# MDR1206AFI register map
Vendor: Milandr; File version: 2.0
CPU: BM-310S0, little endian
Registers are 32-bit, read-write, reset 0x0 unless marked. A register's access mark holds for its fields unless they carry their own. Offsets are from the block's base; [hi:lo] are bit positions; {n}, {i} and the like mark numbered series.

## FLASH_CNTRL — FLASH Memory Controller
Base 0x50018000
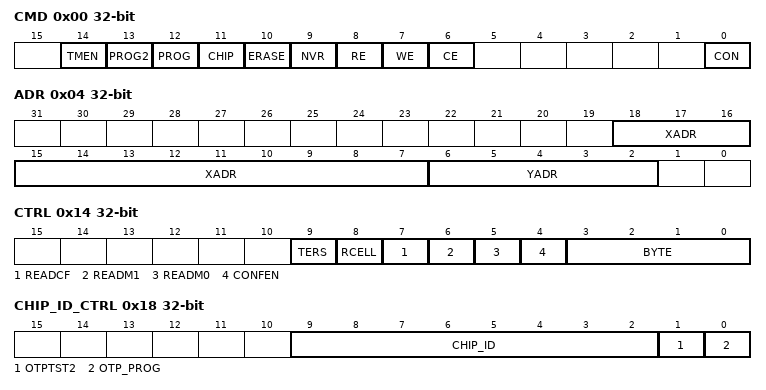
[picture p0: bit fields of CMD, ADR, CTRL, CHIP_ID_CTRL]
0x00 CMD — Control register
  [14] TMEN — Reset FLASH test mode
  [13] PROG2 — Write data from the DI register
  [12] PROG — Enable programming within 32 word lines
  [11] CHIP — Erase the entire sector when ERASE = 1
  [10] ERASE — Erase 512 byte memory page
  [9] NVR — Main/information block selection
  [8] RE — Reading amplifier
  [7] WE — Enable write/erase operations
  [6] CE — Output address ADR[17:2]
  [0] CON — Switching the FLASH memory controller to register control
0x04 ADR — Address register
  [18:7] XADR — Main: XADR[11] - sector number, XADR[10:2] - page address, XADR[1:0] - row address. Info: XADR[6] - sector number, XADR[5:2] - page address, XADR[1:0] - row address
  [6:2] YADR — Word address
0x08 DI — Write data register
0x0C DO — Read data register
0x10 KEY — Key register, 0x8AAA5551 unlocks access
0x14 CTRL — Control and test register
  [9] TERS — Test bit. Always write 0
  [8] RCELL — Test bit. Always write 0
  [7] READCF — Test bit. Always write 0
  [6] READM1 — Test bit. Always write 0
  [5] READM0 — Test bit. Always write 0
  [4] CONFEN — Test bit. Always write 0
  [3:0] BYTE — Selecting a byte from the DI register for programming operations
0x18 CHIP_ID_CTRL — Chip ID and OTP control register
  [9:2] CHIP_ID ro
    215=MDR1206AFI (ID=215); 217=MDR1206FI (ID=217)
  [1] OTPTST2 ro — Test bit
  [0] OTP_PROG — OTP cell program bit
0x1C OTP_KEY — OTP key register, 0x1555AAA8 unlocks access

## I2C — I2C Controller
Base 0x50030000
0x00 PRL — Lower part of the prescaler
  [7:0] PR
0x04 PRH — Higher part of the prescaler
  [7:0] PR
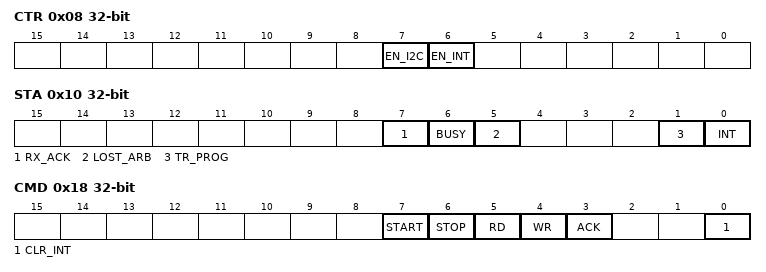
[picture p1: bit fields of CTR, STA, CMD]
0x08 CTR — I2C Control Register
  [7] EN_I2C — Enables I2C operation
  [6] EN_INT — Enables the interrupt generated by the I2C
0x0C RXD ro — Received Data Register
  [7:0] RXD — The last received byte
0x10 STA ro — Status Register
  [7] RX_ACK — Signals if ACK or NACK has been received from a Slave
    0=ACK_Received; 1=NACK_Received
  [6] BUSY — The state of the I2C bus
    0=Stop_Bit_Received; 1=Start_Bit_Received
  [5] LOST_ARB — The loss of the arbitration
    0=ARB_Present; 1=ARB_Lost (The arbitration has been lost. Stop bit has been received without initialization or SDA must be set as high but it is low)
  [1] TR_PROG — The state of the transmission
    0=Completed (Data transmission is completed); 1=In Progress (Data transmission is in progress)
  [0] INT — Interrupt flag
    0=No_Int (Selects ACLK as the clock source); 1=Int_Present (There is an interrupt. Either a byte has been transmitted or the arbitration has been lost)
0x14 TXD — Data for Transmission Register
  [7:0] TXD — Byte to be transmitted via I2C. When address is transmitted zero nit sets the mode^ 0 - write in a Salve, 1 - read out of a Slave
0x18 CMD — I2C Control Register
  [7] START — Sends the start bit
  [6] STOP — Sends the stop bit
  [5] RD — Reads the data of the slave device
  [4] WR — Writes into the slave device
  [3] ACK — Sends ACK
    0=Send_ACK; 1=Send_NACK
  [0] CLR_INT — A write as "1" clears the interrupt

## ADC — ADC Controller
Base 0x50040000
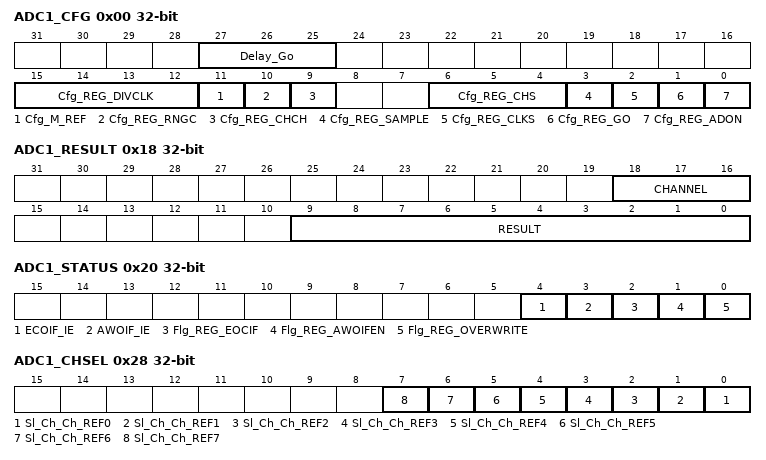
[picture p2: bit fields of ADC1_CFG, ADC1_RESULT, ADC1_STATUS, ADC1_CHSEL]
0x00 ADC1_CFG — ADC1 Configuration Register
  [27:25] Delay_Go — Selects a delay value before the next conversion
  [15:12] Cfg_REG_DIVCLK — Selects the divisor of PCLK
  [11] Cfg_M_REF — Selects the ADC range
    1=SCALE_VREF (ADC scale from 0 to VREF voltage); 0=SCALE_UCCA (ADC scale from 0 to UCCA voltage)
  [10] Cfg_REG_RNGC — Allows the automatic control of overrunning
  [9] Cfg_REG_CHCH — Selects switching of the channels
    1=ON (Channels switching is ON); 0=OFF (Only the selected channel is being used)
  [6:4] Cfg_REG_CHS — Selects the analogue channel for conversion
    7=CH0_ThermoS (CHANNEL_0: Thermosensor); 6=CH1_SAR_AIN1 (CHANNEL_1: SAR_AIN1); 5=CH2_SAR_AIN2 (CHANNEL_2: SAR_AIN2); 4=CH3_SAR_AIN3 (CHANNEL_3: SAR_AIN3); 3=CH4_TestMode (CHANNEL_4: TestMode); 2=CH5_VDD_BD (CHANNEL_5: VDD_BD); 1=CH6_VREF (CHANNEL_6: VREF); 0=CH7_TestMode (CHANNEL_7: TestMode)
  [3] Cfg_REG_SAMPLE — Selects ADC working mode
    0=Single (Selects single working mode); 1=Sequential (Selects sequential working mode)
  [2] Cfg_REG_CLKS — Selects ADC clock source
    0=ACLK (Selects ACLK as the clock source); 1=PCLKd (Selects PCLKd as the clock source)
  [1] Cfg_REG_GO — Starts the conversion
  [0] Cfg_REG_ADON — Turns on the ADC1 controller
0x08 ADC1_H_LEVEL — ADC1 Higher Level Register
  [9:0] REG_H_LEVEL — ADC1 higher level
0x10 ADC1_L_LEVEL — ADC1 Lower Level Register
  [9:0] REG_L_LEVEL — ADC1 lower level
0x18 ADC1_RESULT ro
  [18:16] CHANNEL — Selects the channel to display the result
    1=VREF_R (From 0 to VREF); 0=UCCA_R (From 0 to UCCA)
  [9:0] RESULT — Conversion result
0x20 ADC1_STATUS
  [4] ECOIF_IE — Indicates if an interrupt triggered by Flg_REG_ECOIF is allowed
  [3] AWOIF_IE — Indicates if an interrupt triggered by Flg_REG_AWOIFEN is allowed
  [2] Flg_REG_EOCIF — Signals if there's a result of the conversion
  [1] Flg_REG_AWOIFEN — Signals if the result is out of the boundaries
  [0] Flg_REG_OVERWRITE — Signals if the result has been overwritten in ADC1_RESULT
0x28 ADC1_CHSEL
  [n] Sl_Ch_Ch_REF{n} (n=0..7) — CHANNEL_{n}
0x30 ADC_TRIM — Reference voltage source configuration
  [5:1] BG_TRIM — Bandgap adjustment
